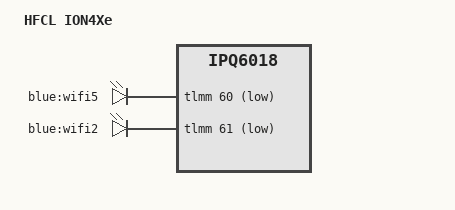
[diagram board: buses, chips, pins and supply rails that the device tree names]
// SPDX-License-Identifier: (GPL-2.0+ OR BSD-3-Clause)
/*
 * IPQ6018 CP01 board device tree source
 *
 * Copyright (c) 2019-2021 The Linux Foundation. All rights reserved.
 */
#include "qcom-ipq6018-hfcl-ion4x.dtsi"

/ {
	model = "HFCL ION4Xe";
	compatible = "hfcl,ion4xe", "qcom,ipq6018-ap-cp01", "qcom,ipq6018";
};

&tlmm {
	leds_pins: leds_pins {
		led_5g {
			pins = "gpio60";
			function = "gpio";
			drive-strength = <8>;
			bias-pull-down;
		};

		led_2g {
			pins = "gpio61";
			function = "gpio";
			drive-strength = <8>;
			bias-pull-down;
		};
	};
};

&leds {
	led@60 {
		label = "blue:wifi5";
		gpios = <&tlmm 60 GPIO_ACTIVE_LOW>;
		linux,default-trigger = "led_5g";
		default-state = "off";
	};
	led@61 {
		label = "blue:wifi2";
		gpios = <&tlmm 61 GPIO_ACTIVE_LOW>;
		linux,default-trigger = "led_2g";
		default-state = "off";
	};
};
